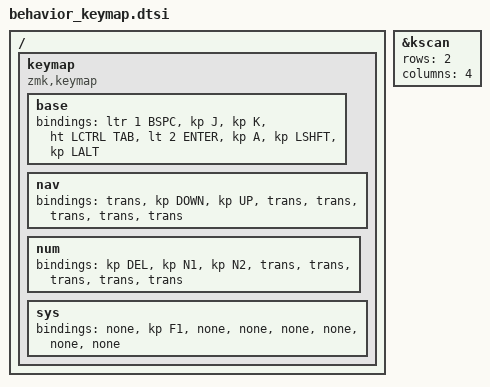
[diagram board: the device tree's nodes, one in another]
// Simulator tests for src/behaviors/behavior_layer_tap_repeat.c; run ./test.sh
#include <dt-bindings/zmk/keys.h>
#include <behaviors.dtsi>
#include <dt-bindings/zmk/kscan_mock.h>

// Positions: 0 = Bksp/Nav (ltr), 1 = J, 2 = K, 3 = Tab/Ctrl, 4 = Enter/Num, 5 = A, 6 = Shift, 7 = Alt
&kscan { rows = <2>; columns = <4>; };

// The real behaviors from config/common/, with this test layout's positions.
#define HS_FOLLOW_POS 5       // A (these tests don't use hs/hsp)
#define HSP_FOLLOW_POS 6      // Shift
#define SYSTEM_COMBO_POSITIONS 4 0
#include "../../config/common/behaviors.dtsi"
#include "../../config/common/combos.dtsi"

/ {
    keymap {
        compatible = "zmk,keymap";
        base { bindings = <&ltr 1 BSPC &kp J &kp K &ht LCTRL TAB &lt 2 ENTER &kp A &kp LSHFT &kp LALT>; };
        nav  { bindings = <&trans &kp DOWN &kp UP &trans &trans &trans &trans &trans>; };
        num  { bindings = <&kp DEL &kp N1 &kp N2 &trans &trans &trans &trans &trans>; };
        sys  { bindings = <&none &kp F1 &none &none &none &none &none &none>; };
    };
};
